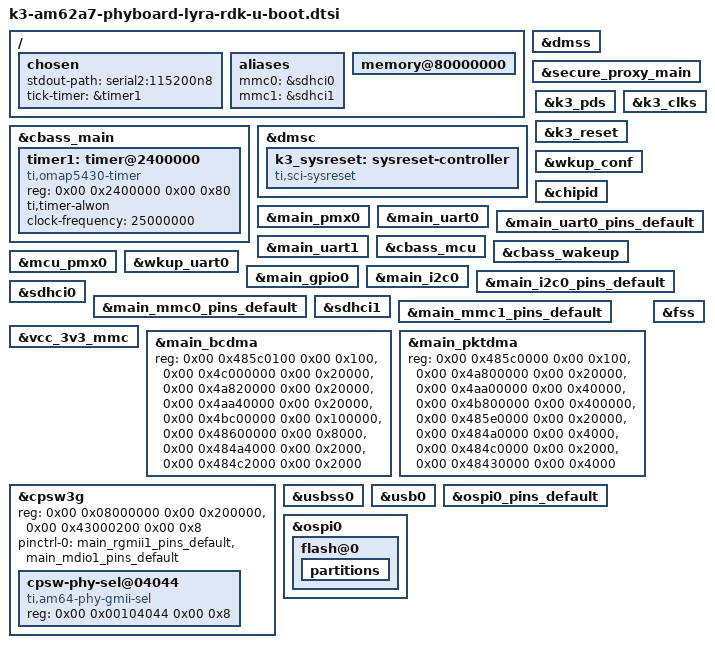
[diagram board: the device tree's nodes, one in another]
// SPDX-License-Identifier: GPL-2.0
/*
 * phyCORE-AM62Ax dts file for SPLs
 * Copyright (C) 2023 PHYTEC America LLC
 * Author: Garrett Giordano <ggiordano@phytec.com>
 *
 * Product homepage:
 * https://www.phytec.com/product/phycore-am62ax
 */

#include "k3-am62a-phycore-som-binman.dtsi"

/ {
	chosen {
		stdout-path = "serial2:115200n8";
		tick-timer = &timer1;
	};

	aliases {
		mmc0 = &sdhci0;
		mmc1 = &sdhci1;
	};

	memory@80000000 {
		bootph-all;
	};
};

&cbass_main {
	bootph-all;

	timer1: timer@2400000 {
		compatible = "ti,omap5430-timer";
		reg = <0x00 0x2400000 0x00 0x80>;
		ti,timer-alwon;
		clock-frequency = <25000000>;
		bootph-all;
	};
};

&dmss {
	bootph-all;
};

&secure_proxy_main {
	bootph-all;
};

&dmsc {
	bootph-all;
};

&k3_pds {
	bootph-all;
};

&k3_clks {
	bootph-all;
};

&k3_reset {
	bootph-all;
};

&wkup_conf {
	bootph-all;
};

&chipid {
	bootph-all;
};

&main_pmx0 {
	bootph-all;
};

&main_uart0 {
	bootph-all;
};

&main_uart0_pins_default {
	bootph-all;
};

&main_uart1 {
	bootph-all;
};

&cbass_mcu {
	bootph-all;
};

&cbass_wakeup {
	bootph-all;
};

&mcu_pmx0 {
	bootph-all;
};

&wkup_uart0 {
	bootph-all;
};

&main_gpio0 {
	bootph-all;
};

&main_i2c0 {
	bootph-all;
};

&main_i2c0_pins_default {
	bootph-all;
};

&sdhci0 {
	bootph-all;
};

&main_mmc0_pins_default {
	bootph-all;
};

&sdhci1 {
	bootph-all;
};

&main_mmc1_pins_default {
	bootph-all;
};

&k3_reset {
	bootph-all;
};

&dmsc {
	bootph-all;
	k3_sysreset: sysreset-controller {
		compatible = "ti,sci-sysreset";
		bootph-all;
	};
};

&vcc_3v3_mmc {
	bootph-all;
};

&main_bcdma {
	bootph-all;
	reg = <0x00 0x485c0100 0x00 0x100>,
	      <0x00 0x4c000000 0x00 0x20000>,
	      <0x00 0x4a820000 0x00 0x20000>,
	      <0x00 0x4aa40000 0x00 0x20000>,
	      <0x00 0x4bc00000 0x00 0x100000>,
	      <0x00 0x48600000 0x00 0x8000>,
	      <0x00 0x484a4000 0x00 0x2000>,
	      <0x00 0x484c2000 0x00 0x2000>;
	reg-names = "gcfg", "bchanrt", "rchanrt", "tchanrt",
		    "ringrt", "cfg", "tchan", "rchan";
};

&main_pktdma {
	bootph-all;
	reg = <0x00 0x485c0000 0x00 0x100>,
	      <0x00 0x4a800000 0x00 0x20000>,
	      <0x00 0x4aa00000 0x00 0x40000>,
	      <0x00 0x4b800000 0x00 0x400000>,
	      <0x00 0x485e0000 0x00 0x20000>,
	      <0x00 0x484a0000 0x00 0x4000>,
	      <0x00 0x484c0000 0x00 0x2000>,
	      <0x00 0x48430000 0x00 0x4000>;
	reg-names = "gcfg", "rchanrt", "tchanrt", "ringrt",
		    "cfg", "tchan", "rchan", "rflow";
};

&cpsw3g {
	reg = <0x00 0x08000000 0x00 0x200000>,
	      <0x00 0x43000200 0x00 0x8>;
	reg-names = "cpsw_nuss", "mac_efuse";
	/delete-property/ ranges;
	pinctrl-0 = <&main_rgmii1_pins_default
		     &main_mdio1_pins_default>; /* HACK: MDIO driver is not DM enabled */
	bootph-all;

	cpsw-phy-sel@04044 {
		compatible = "ti,am64-phy-gmii-sel";
		reg = <0x00 0x00104044 0x00 0x8>;
		bootph-all;
	};
};

&usbss0 {
	bootph-all;
};

&usb0 {
	bootph-all;
};

&fss {
	bootph-all;
};

&ospi0_pins_default {
	bootph-all;
};

&ospi0 {
	bootph-all;

	flash@0 {
		bootph-all;

		partitions {
			bootph-all;
		};
	};
};
